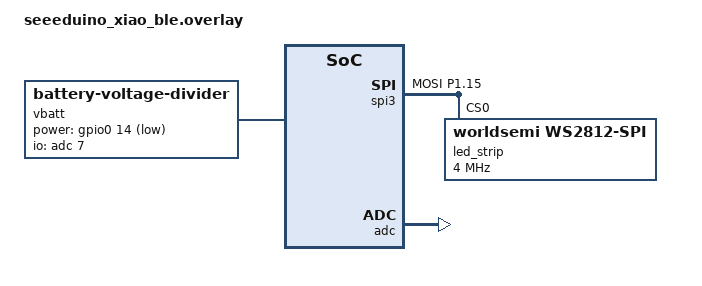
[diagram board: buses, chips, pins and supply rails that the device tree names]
#include <dt-bindings/led/led.h>

/ {
    chosen {
        zmk,underglow = &led_strip;
        zmk,battery = &vbatt;
    };

    vbatt: vbatt {
        compatible = "zmk,battery-voltage-divider";
        io-channels = <&adc 7>;
        power-gpios = <&gpio0 14 (GPIO_OPEN_DRAIN | GPIO_ACTIVE_LOW)>;
        output-ohms = <510000>;
        full-ohms = <(1000000 + 510000)>;
    };
};

&pinctrl {
    spi3_default: spi3_default {
        group1 {
            psels = <NRF_PSEL(SPIM_MOSI, 1, 15)>;
        };
    };

    spi3_sleep: spi3_sleep {
        group1 {
            psels = <NRF_PSEL(SPIM_MOSI, 1, 15)>;
            low-power-enable;
        };
    };
};

&spi3 {
    compatible = "nordic,nrf-spim";
    status = "okay";

    pinctrl-0 = <&spi3_default>;
    pinctrl-1 = <&spi3_sleep>;
    pinctrl-names = "default", "sleep";

    led_strip: ws2812@0 {
        compatible = "worldsemi,ws2812-spi";
        reg = <0>;
        spi-max-frequency = <4000000>;
        chain-length = <8>; /* 実LED数 */
        spi-one-frame = <0x70>;
        spi-zero-frame = <0x40>;
        color-mapping = <LED_COLOR_ID_GREEN LED_COLOR_ID_RED LED_COLOR_ID_BLUE>;
    };
};

&adc {
    status = "okay";
};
